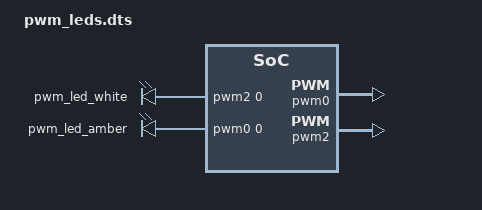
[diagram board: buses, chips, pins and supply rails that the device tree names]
/* Copyright 2022 The ChromiumOS Authors
 * Use of this source code is governed by a BSD-style license that can be
 * found in the LICENSE file.
 */

#include "led_policy.dts"

/ {
	pwmleds {
		compatible = "pwm-leds";
		pwm_led_white: pwm_led_0 {
			pwms = <&pwm2 0 PWM_HZ(4800) PWM_POLARITY_INVERTED
				&pwm0 0 PWM_HZ(4800) PWM_POLARITY_INVERTED>;
		};
		pwm_led_amber: pwm_led_1 {
			pwms = <&pwm0 0 PWM_HZ(4800) PWM_POLARITY_INVERTED
				&pwm2 0 PWM_HZ(4800) PWM_POLARITY_INVERTED>;
		};
	};

	pwm-led-pins {
		compatible = "cros-ec,pwm-led-pins";

		battery_led: battery-led {
			led-id = "EC_LED_ID_BATTERY_LED";
			led-pwms = <&pwm_led_amber &pwm_led_white>;

			/* Amber - turn on yellow LED */
			color_amber: color-amber {
				led-color = "LED_AMBER";
				br-color = "EC_LED_COLOR_AMBER";
				led-values = <100 0>;
			};

			/* White - turn on white LED */
			color_white: color-white {
				led-color = "LED_WHITE";
				br-color = "EC_LED_COLOR_WHITE";
				led-values = <0 100>;
			};

			/* Off - turn off both LEDs */
			color_off: color-off {
				led-color = "LED_OFF";
				led-values = <0 0>;
			};
		};
	};
};

/* LED2 white*/
&pwm0 {
	status = "okay";
	clock-bus = "NPCX_CLOCK_BUS_LFCLK";
	pinctrl-0 = <&pwm0_gpc3>;
	pinctrl-names = "default";
};

/* LED1 amber*/
&pwm2 {
	status = "okay";
	clock-bus = "NPCX_CLOCK_BUS_LFCLK";
	pinctrl-0 = <&pwm2_gpc4>;
	pinctrl-names = "default";
};
